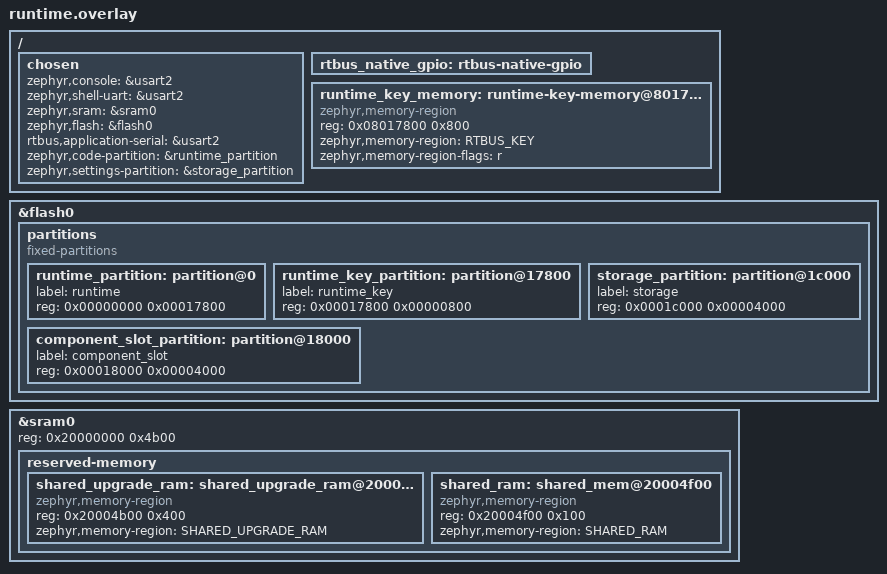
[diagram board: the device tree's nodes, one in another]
/* SPDX-License-Identifier: MPL-2.0 */
/ {
	chosen {
		zephyr,console = &usart2;
		zephyr,shell-uart = &usart2;
		zephyr,sram = &sram0;
		zephyr,flash = &flash0;
		rtbus,application-serial = &usart2;
		zephyr,code-partition = &runtime_partition;
		zephyr,settings-partition = &storage_partition;
	};

	rtbus_native_gpio: rtbus-native-gpio {
		/*
		 * Application GPIO export map.
		 *
		 * Only board-owned pins that are safe for native applications should
		 * be listed here. Leaving this empty avoids exposing runtime,
		 * peripheral, wake, and low-power pins as raw GPIO ABI.
		 */
	};
};

&flash0 {
	/delete-node/ partitions;
	partitions {
		compatible = "fixed-partitions";
		#address-cells = <1>;
		#size-cells = <1>;

		runtime_partition: partition@0 {
			label = "runtime";
			reg = <0x00000000 0x00017800>;
		};

		runtime_key_partition: partition@17800 {
			label = "runtime_key";
			reg = <0x00017800 0x00000800>;
		};

		component_slot_partition: partition@18000 {
			label = "component_slot";
			reg = <0x00018000 0x00004000>;
		};

		storage_partition: partition@1c000 {
			label = "storage";
			reg = <0x0001c000 0x00004000>;
		};
	};
};

&sram0 {
	reg = <0x20000000 0x4b00>;

	reserved-memory {
		#address-cells = <1>;
		#size-cells = <1>;
		ranges;

		shared_upgrade_ram: shared_upgrade_ram@20004b00 {
			compatible = "zephyr,memory-region";
			reg = <0x20004b00 0x400>;
			zephyr,memory-region = "SHARED_UPGRADE_RAM";
		};

		shared_ram: shared_mem@20004f00 {
			compatible = "zephyr,memory-region";
			reg = <0x20004f00 0x100>;
			zephyr,memory-region = "SHARED_RAM";
		};
	};
};

/* Link the default public key into the same independent Flash partition. */
/ {
	runtime_key_memory: runtime-key-memory@8017800 {
		compatible = "zephyr,memory-region";
		reg = <0x08017800 0x800>;
		zephyr,memory-region = "RTBUS_KEY";
		zephyr,memory-region-flags = "r";
	};
};
